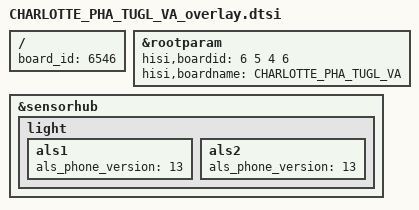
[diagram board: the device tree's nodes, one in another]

/**
 * Copyright (C) 2014 Hisilicon Ltd.
 *
 *  This program is free software; you can redistribute it and/or modify
 *  it under the terms of the GNU General Public License version 2 as
 *  publishhed by the Free Software Foundation.
 */

/include/ "CHARLOTTE_PHA_TUGL_VN1_overlay.dtsi"

/ {
        board_id = <6546>;
};

&rootparam {
    hisi,boardid = <6 5 4 6>;
    hisi,boardname = "CHARLOTTE_PHA_TUGL_VA";
};


&sensorhub {
	light{
		als1{
			als_phone_version = <13>;
		};
		als2{
			als_phone_version = <13>;
		};
	};
};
